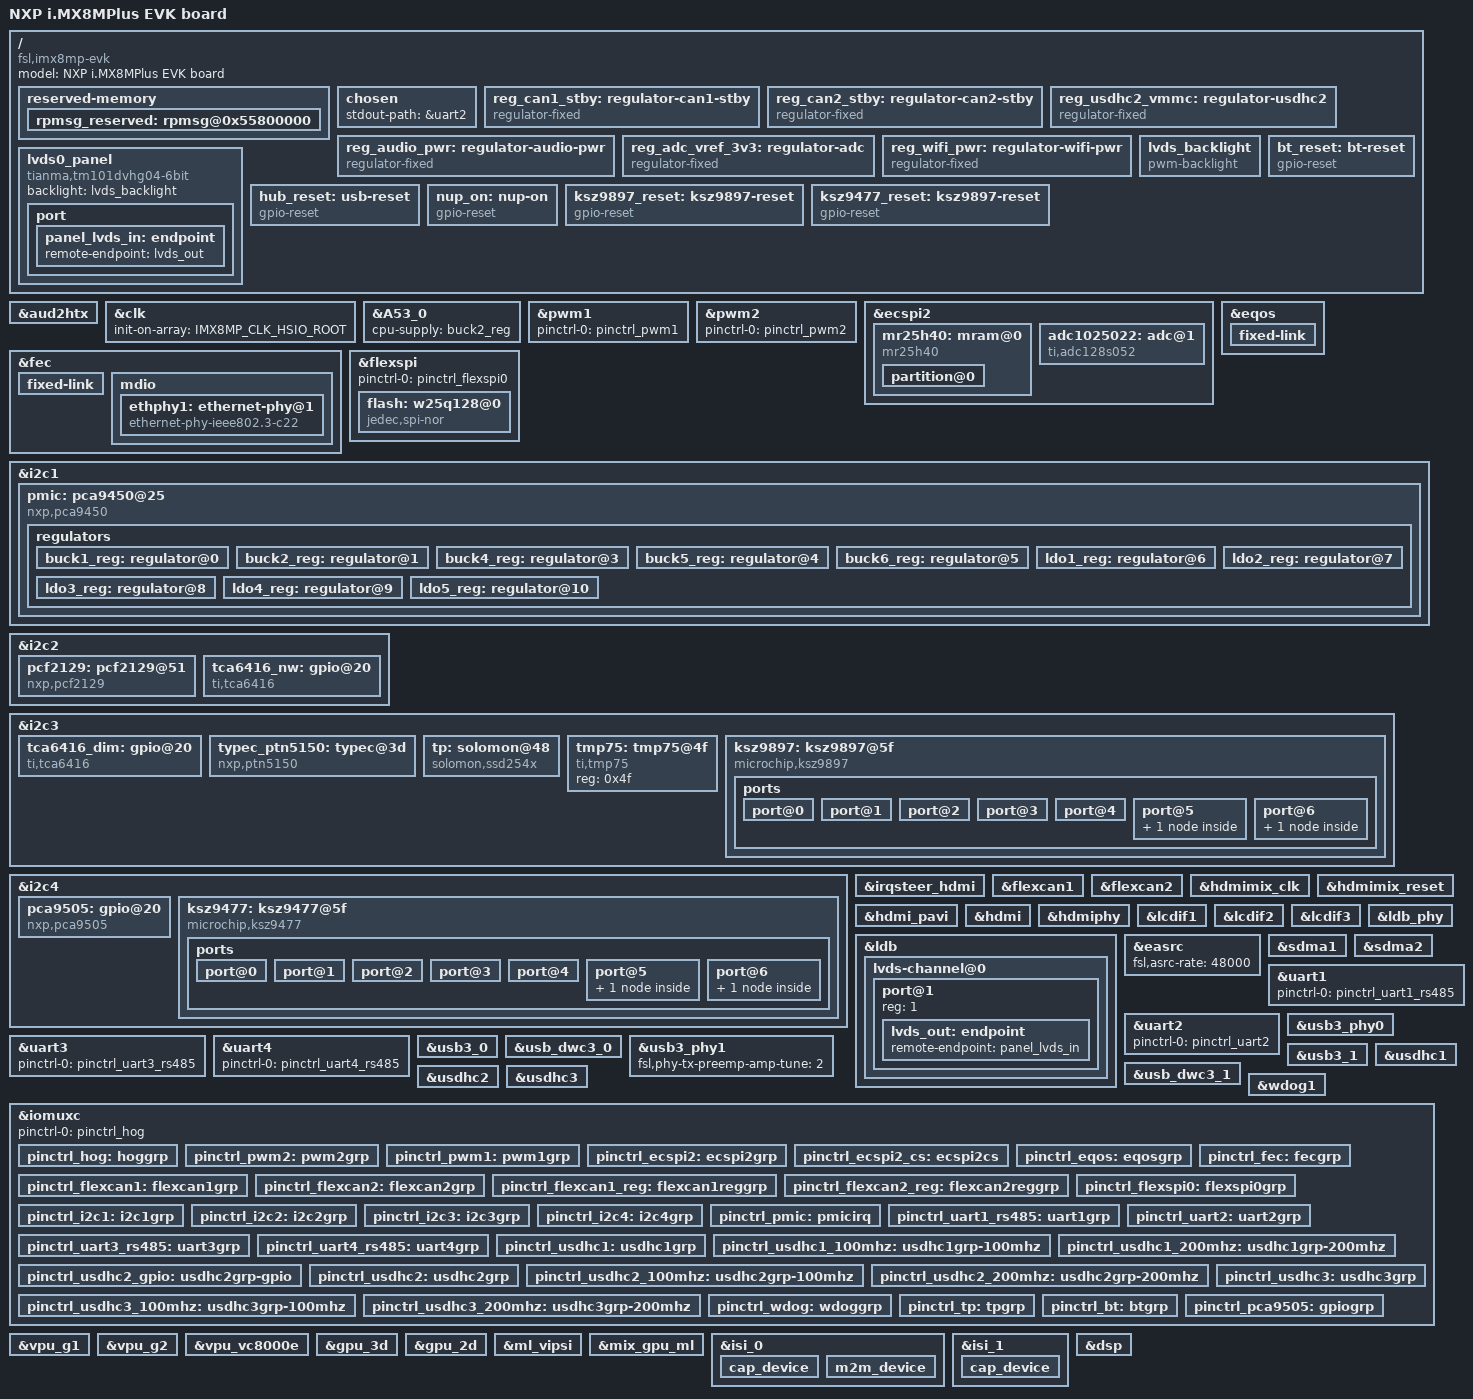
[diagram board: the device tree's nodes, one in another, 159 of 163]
// SPDX-License-Identifier: (GPL-2.0+ OR MIT)
/*
 * Copyright 2019 NXP
 */

/dts-v1/;

#include <dt-bindings/usb/pd.h>
#include "imx8mp-common.dtsi"

/ {
	model = "NXP i.MX8MPlus EVK board";
	compatible = "fsl,imx8mp-evk", "fsl,imx8mp";

	reserved-memory {
		#address-cells = <2>;
		#size-cells = <2>;
		ranges;

		rpmsg_reserved: rpmsg@0x55800000 {
			no-map;
			reg = <0 0x55800000 0 0x800000>;
		};
	};

	chosen {
		stdout-path = &uart2;
	};

	reg_can1_stby: regulator-can1-stby {
		compatible = "regulator-fixed";
		regulator-name = "can1-stby";
		pinctrl-names = "default";
		pinctrl-0 = <&pinctrl_flexcan1_reg>;
		regulator-min-microvolt = <3300000>;
		regulator-max-microvolt = <3300000>;
		gpio = <&gpio4 1 GPIO_ACTIVE_LOW>;
		enable-active-low;
	};

	reg_can2_stby: regulator-can2-stby {
		compatible = "regulator-fixed";
		regulator-name = "can2-stby";
		pinctrl-names = "default";
		pinctrl-0 = <&pinctrl_flexcan2_reg>;
		regulator-min-microvolt = <3300000>;
		regulator-max-microvolt = <3300000>;
		gpio = <&gpio1 11 GPIO_ACTIVE_LOW>;
		enable-active-low;
	        status = "okay";
	};

	reg_usdhc2_vmmc: regulator-usdhc2 {
		compatible = "regulator-fixed";
		regulator-name = "VSD_3V3";
		regulator-min-microvolt = <3300000>;
		regulator-max-microvolt = <3300000>;
		gpio = <&gpio2 19 GPIO_ACTIVE_HIGH>;
		enable-active-high;
		startup-delay-us = <100>;
		off-on-delay-us = <12000>;
	};

	reg_audio_pwr: regulator-audio-pwr {
		compatible = "regulator-fixed";
		regulator-name = "audio-pwr";
		regulator-min-microvolt = <3300000>;
		regulator-max-microvolt = <3300000>;
		gpio = <&gpio4 29 GPIO_ACTIVE_HIGH>;
		enable-active-high;
		regulator-always-on;
	};

	reg_adc_vref_3v3: regulator-adc {
                compatible = "regulator-fixed";
                regulator-name = "3V3";
                regulator-min-microvolt = <3327272>;
                regulator-max-microvolt = <3327272>;
                regulator-always-on;
        };

	reg_wifi_pwr: regulator-wifi-pwr {
                compatible = "regulator-fixed";
                regulator-name = "wifi-pwr";
                regulator-min-microvolt = <3300000>;
                regulator-max-microvolt = <3300000>;
                gpio = <&gpio2 8 GPIO_ACTIVE_HIGH>;
                enable-active-high;
                regulator-always-on;
                startup-delay-us = <10000>;
                off-on-delay-us = <12000>;
        };

	lvds_backlight: lvds_backlight {
		compatible = "pwm-backlight";
		pwms = <&pwm1 0 100000>;
		status = "okay";

		brightness-levels = < 0  1  2  3  4  5  6  7  8  9
				     10 11 12 13 14 15 16 17 18 19
				     20 21 22 23 24 25 26 27 28 29
				     30 31 32 33 34 35 36 37 38 39
				     40 41 42 43 44 45 46 47 48 49
				     50 51 52 53 54 55 56 57 58 59
				     60 61 62 63 64 65 66 67 68 69
				     70 71 72 73 74 75 76 77 78 79
				     80 81 82 83 84 85 86 87 88 89
				     90 91 92 93 94 95 96 97 98 99
				    100>;
		default-brightness-level = <80>;
	};

	lvds0_panel {
		compatible = "tianma,tm101dvhg04-6bit";
		backlight = <&lvds_backlight>;

		port {
			panel_lvds_in: endpoint {
				remote-endpoint = <&lvds_out>;
			};
		};
	};

	bt_reset: bt-reset {
		compatible = "gpio-reset";
		reset-gpios = <&gpio2 7 GPIO_ACTIVE_LOW>;
		reset-delay-us = <1000>;
		#reset-cells = <0>;
	};

	hub_reset: usb-reset {
		compatible = "gpio-reset";
		reset-gpios = <&pca9505 27 1>;
		#reset-cells = <0>;
		default-state = "off";
	};

	nup_on: nup-on {
               compatible = "gpio-reset";
               reset-gpios = <&pca9505 25 1>;
               #reset-cells = <0>;
               default-state = "off";
	};

	ksz9897_reset: ksz9897-reset {
		compatible = "gpio-reset";
		reset-gpios = <&gpio2 10 1>;
		#reset-cells = <0>;
		default-state = "off";
	};

	ksz9477_reset: ksz9897-reset {
		compatible = "gpio-reset";
		reset-gpios = <&gpio4 2 1>;
		#reset-cells = <0>;
		default-state = "off";
	};
};

&aud2htx {
	status = "okay";
};

&clk {
	init-on-array = <IMX8MP_CLK_HSIO_ROOT>;
};

&A53_0 {
	cpu-supply = <&buck2_reg>;
};

&pwm1 {
	pinctrl-names = "default";
	pinctrl-0 = <&pinctrl_pwm1>;
	status = "okay";
};

&pwm2 {
	pinctrl-names = "default";
	pinctrl-0 = <&pinctrl_pwm2>;
	status = "okay";
};

&ecspi2 {
	pinctrl-names = "default";
	fsl,spi-num-chipselects = <2>;
	num-cs = <2>;
	pinctrl-0 = <&pinctrl_ecspi2 &pinctrl_ecspi2_cs>;
	cs-gpios = <&gpio5 13 GPIO_ACTIVE_LOW
                    &gpio5 1 GPIO_ACTIVE_LOW>;
	status = "okay";

	mr25h40: mram@0 {
              #address-cells = <1>;
              #size-cells = <1>;
              compatible = "mr25h40", "jedec,spi-nor";
              reg = <0 0x00000000 0x00080000>;
              spi-max-frequency = <30000000>;

              partition@0 {
                      label = "mram";
                      reg = <0x00000000 0x00080000>;
              };
	};


        /* The actual chip is a ADC102S022, 10bit 8-channel. Driver is for a 12-bit,
        so the two MSBs will be 0 */
        adc1025022: adc@1 {
                reg = <1>;
                #address-cells = <1>;
                #size-cells = <0>;
                compatible = "ti,adc128s052";
                vref-supply = <&reg_adc_vref_3v3>;
                spi-max-frequency = <1000000>;
                status = "okay";
        };

};

&eqos {
	pinctrl-names = "default";
	pinctrl-0 = <&pinctrl_eqos>;
	phy-mode = "rgmii-id";
	resets = <&ksz9897_reset>;
	status = "okay";

        fixed-link {
                speed = <1000>;
                full-duplex;
        };
};

&fec {
	pinctrl-names = "default";
	pinctrl-0 = <&pinctrl_fec>;
	phy-mode = "rgmii-txid";
	phy-handle = <&ethphy1>;
	resets = <&ksz9477_reset>;
	fsl,magic-packet;
	status = "okay";

        fixed-link {
                speed = <1000>;
                full-duplex;
        };

	mdio {
		#address-cells = <1>;
		#size-cells = <0>;

		ethphy1: ethernet-phy@1 {
			compatible = "ethernet-phy-ieee802.3-c22";
			reg = <1>;
			micrel,led-mode = <1>;
                        eee-broken-100tx;
                        eee-broken-1000t;
		};
	};
};

&flexspi {
	pinctrl-names = "default";
	pinctrl-0 = <&pinctrl_flexspi0>;
	status = "okay";

        /*      Winbond 25Q128JWSIQ SPI NOR flash       */
        flash: w25q128@0 {
                #address-cells = <1>;
                #size-cells = <1>;
                compatible = "jedec,spi-nor";
                m25p,fast-read;
                spi-max-frequency = <40000000>;
                reg = <0>;
                status = "okay";
        };
};


&i2c1 {
	clock-frequency = <100000>;
	pinctrl-names = "default";
	pinctrl-0 = <&pinctrl_i2c1>;
	status = "okay";

	pmic: pca9450@25 {
		reg = <0x25>;
		compatible = "nxp,pca9450";
		/* PMIC PCA9450 PMIC_nINT GPIO1_IO3 */
		pinctrl-0 = <&pinctrl_pmic>;
		gpio_intr = <&gpio1 3 GPIO_ACTIVE_LOW>;

		regulators {
			#address-cells = <1>;
			#size-cells = <0>;

			pca9450,pmic-buck2-uses-i2c-dvs;
			/* Run/Standby voltage */
			pca9450,pmic-buck2-dvs-voltage = <950000>, <850000>;

			buck1_reg: regulator@0 {
				reg = <0>;
				regulator-compatible = "buck1";
				regulator-min-microvolt = <600000>;
				regulator-max-microvolt = <2187500>;
				regulator-boot-on;
				regulator-always-on;
				regulator-ramp-delay = <3125>;
			};

			buck2_reg: regulator@1 {
				reg = <1>;
				regulator-compatible = "buck2";
				regulator-min-microvolt = <600000>;
				regulator-max-microvolt = <2187500>;
				regulator-boot-on;
				regulator-always-on;
				regulator-ramp-delay = <3125>;
			};

			buck4_reg: regulator@3 {
				reg = <3>;
				regulator-compatible = "buck4";
				regulator-min-microvolt = <600000>;
				regulator-max-microvolt = <3400000>;
				regulator-boot-on;
				regulator-always-on;
			};

			buck5_reg: regulator@4 {
				reg = <4>;
				regulator-compatible = "buck5";
				regulator-min-microvolt = <600000>;
				regulator-max-microvolt = <3400000>;
				regulator-boot-on;
				regulator-always-on;
			};

			buck6_reg: regulator@5 {
				reg = <5>;
				regulator-compatible = "buck6";
				regulator-min-microvolt = <600000>;
				regulator-max-microvolt = <3400000>;
				regulator-boot-on;
				regulator-always-on;
			};

			ldo1_reg: regulator@6 {
				reg = <6>;
				regulator-compatible = "ldo1";
				regulator-min-microvolt = <1600000>;
				regulator-max-microvolt = <3300000>;
				regulator-boot-on;
				regulator-always-on;
			};

			ldo2_reg: regulator@7 {
				reg = <7>;
				regulator-compatible = "ldo2";
				regulator-min-microvolt = <800000>;
				regulator-max-microvolt = <1150000>;
				regulator-boot-on;
				regulator-always-on;
			};

			ldo3_reg: regulator@8 {
				reg = <8>;
				regulator-compatible = "ldo3";
				regulator-min-microvolt = <800000>;
				regulator-max-microvolt = <3300000>;
				regulator-boot-on;
				regulator-always-on;
			};

			ldo4_reg: regulator@9 {
				reg = <9>;
				regulator-compatible = "ldo4";
				regulator-min-microvolt = <800000>;
				regulator-max-microvolt = <3300000>;
				regulator-boot-on;
				regulator-always-on;
			};

			ldo5_reg: regulator@10 {
				reg = <10>;
				regulator-compatible = "ldo5";
				regulator-min-microvolt = <1800000>;
				regulator-max-microvolt = <3300000>;
			};
		};
	};
};

&i2c2 {
	clock-frequency = <100000>;
	pinctrl-names = "default";
	pinctrl-0 = <&pinctrl_i2c2>;
	status = "okay";

	/* RTC */
	pcf2129: pcf2129@51 {
		compatible = "nxp,pcf2129";
		reg = <0x51>;
		interrupt-parent = <&pca9505>;
		interrupts = <7 IRQ_TYPE_EDGE_FALLING>;
	};

	tca6416_nw: gpio@20 {
		compatible = "ti,tca6416";
		reg = <0x20>;
		gpio-controller;
		#gpio-cells = <2>;
	};
};

&i2c3 {
	clock-frequency = <100000>;
	pinctrl-names = "default";
	pinctrl-0 = <&pinctrl_i2c3>;
	status = "okay";

	tca6416_dim: gpio@20 {
		compatible = "ti,tca6416";
		reg = <0x20>;
		gpio-controller;
		#gpio-cells = <2>;
	};

	typec_ptn5150: typec@3d {
		compatible = "nxp,ptn5150";
		reg = <0x3d>;
		vbus-gpios = <&pca9505 18 GPIO_ACTIVE_HIGH>;
		status = "okay";
	};

	tp: solomon@48 {
		compatible = "solomon,ssd254x";
		pinctrl-names = "default";
		pinctrl-0 = <&pinctrl_tp>;
		reg = <0x48>;
		gpios = <&gpio5 3 1>, /* interrupt */
		<&tca6416_dim 0 1>; /* Reset */
	};

       /*      temperature sensor      */
       tmp75: tmp75@4f {
               compatible = "ti,tmp75";
               reg = <0x4f>;
               status = "okay";
       };

       ksz9897: ksz9897@5f {
               compatible = "microchip,ksz9897";
               reg = <0x5f>;
               phy-mode = "rgmii-txid";

               interrupt-parent = <&gpio2>;
               interrupts = <11 IRQ_TYPE_LEVEL_LOW>;
               status = "okay";
               ports {
                       #address-cells = <1>;
                       #size-cells = <0>;
                       port@0 {
                               reg = <0>;
                               label = "lan1";
                       };
                       port@1 {
                               reg = <1>;
                               label = "lan2";
                       };
                       port@2 {
                               reg = <2>;
                               label = "lan3";
                       };
                       port@3 {
                               reg = <3>;
                               label = "lan4";
                       };
                       port@4 {
                               reg = <4>;
                               label = "lan5";
                       };
                       port@5 {
                               reg = <5>;
                               label = "cpu";
                               ethernet = <&eqos>;
                               fixed-link {
                                      speed = <1000>;
                                      full-duplex;
                               };
                       };
                       port@6 {
                              reg = <6>;
                              label = "lan6";
                              fixed-link {
                                     speed = <1000>;
                                     full-duplex;
                              };
                       };
               };
       };

};

&i2c4 {
        clock-frequency = <100000>;
        pinctrl-names = "default";
        pinctrl-0 = <&pinctrl_i2c4>;
        status = "okay";

	pca9505: gpio@20 {
		compatible = "nxp,pca9505";
		reg = <0x20>;
		gpio-controller;
		#gpio-cells = <2>;
		status = "okay";
	};

	ksz9477: ksz9477@5f {
		compatible = "microchip,ksz9477";
		reg = <0x5f>;
		phy-mode = "rgmii-rxid";

		interrupt-parent = <&gpio4>;
		interrupts = <3 IRQ_TYPE_LEVEL_LOW>;
		status = "okay";
		ports {
			#address-cells = <1>;
			#size-cells = <0>;
			port@0 {
				reg = <0>;
				label = "lan1";
			};
			port@1 {
				reg = <1>;
				label = "lan2";
			};
			port@2 {
				reg = <2>;
				label = "lan3";
			};
			port@3 {
				reg = <3>;
				label = "lan4";
			};
			port@4 {
				reg = <4>;
				label = "lan5";
			};
			port@5 {
				reg = <5>;
				label = "cpu";
				ethernet = <&fec>;
				fixed-link {
					speed = <1000>;
					full-duplex;
				};
			};
			port@6 {
				reg = <6>;
				label = "lan6";
				fixed-link {
					speed = <1000>;
					full-duplex;
					};
			};
		};
	};
};


&irqsteer_hdmi {
	status = "okay";
};

&flexcan1 {
	pinctrl-names = "default";
	pinctrl-0 = <&pinctrl_flexcan1>;
	xceiver-supply = <&reg_can1_stby>;
	status = "okay";
};

&flexcan2 {
	pinctrl-names = "default";
	pinctrl-0 = <&pinctrl_flexcan2>;
	xceiver-supply = <&reg_can2_stby>;
	status = "okay";
};

&hdmimix_clk {
	status = "okay";
};

&hdmimix_reset {
	status = "okay";
};

&hdmi_pavi {
	status = "okay";
};

&hdmi {
	status = "okay";
};

&hdmiphy {
	status = "okay";
};

&lcdif1 {
	status = "okay";
};

&lcdif2 {
        status = "okay";
};

&lcdif3 {
	status = "okay";

	thres-low  = <1 2>;             /* (FIFO * 1 / 2) */
	thres-high = <3 4>;             /* (FIFO * 3 / 4) */
};

&ldb {
	status = "okay";

	lvds-channel@0 {
		fsl,data-mapping = "jeida";
		fsl,data-width = <24>;
		status = "okay";

		port@1 {
			reg = <1>;

			lvds_out: endpoint {
				remote-endpoint = <&panel_lvds_in>;
			};
		};
	};
};

&ldb_phy {
	status = "okay";
};

&easrc {
	fsl,asrc-rate  = <48000>;
	status = "okay";
};

&sdma1 {
	status = "okay";
};

&sdma2 {
	status = "okay";
};

&uart1 { /* For RS485 */
	pinctrl-names = "default";
	pinctrl-0 = <&pinctrl_uart1_rs485>;
	//assigned-clocks = <&clk IMX8MP_CLK_UART1>;
	//assigned-clock-parents = <&clk IMX8MP_SYS_PLL1_80M>;
	status = "okay";
};

&uart2 {
	/* console */
	pinctrl-names = "default";
	pinctrl-0 = <&pinctrl_uart2>;
	status = "okay";
};

&uart3 { /* For RS485 */
	pinctrl-names = "default";
	pinctrl-0 = <&pinctrl_uart3_rs485>;
	//assigned-clocks = <&clk IMX8MP_CLK_UART3>;
	//assigned-clock-parents = <&clk IMX8MP_SYS_PLL1_80M>;
	//fsl,uart-has-rtscts;
	status = "okay";
	//status = "disable";
};

&uart4 { /* for RS485-A,B */
	pinctrl-names = "default";
	pinctrl-0 = <&pinctrl_uart4_rs485>;
	//assigned-clocks = <&clk IMX8MP_CLK_UART3>;
	//assigned-clock-parents = <&clk IMX8MP_SYS_PLL1_80M>;
	//fsl,uart-has-rtscts;
	status = "okay";
	//status = "disable";
};

&usb3_phy0 {
	//vbus-power-supply = <&typec1_ptn5150>;
	fsl,phy-tx-vref-tune = <6>;
	fsl,phy-tx-rise-tune = <0>;
	fsl,phy-tx-preemp-amp-tune = <3>;
	fsl,phy-comp-dis-tune = <7>;
	fsl,pcs-tx-deemph-3p5db = <0x21>;
	fsl,phy-pcs-tx-swing-full = <0x7f>;
	status = "okay";
};

&usb3_0 {
	status = "okay";
};

&usb_dwc3_0 {
	//dr_mode = "peripheral";
	//dr_mode = "host";
	dr_mode = "otg";
	extcon = <&typec_ptn5150>;
	hnp-disable;
	srp-disable;
	adp-disable;
	maximum-speed = "full-speed";
	//usb-role-switch;
	status = "okay";
};

&usb3_phy1 {
	fsl,phy-tx-preemp-amp-tune = <2>;
	status = "okay";
};

&usb3_1 {
	status = "okay";
};

&usb_dwc3_1 {
	//dr_mode = "peripheral";
	resets = <&hub_reset>;
        dr_mode = "host";
        status = "okay";
};

&usdhc1 { /* wifi */
	pinctrl-names = "default", "state_100mhz", "state_200mhz";
	pinctrl-0 = <&pinctrl_usdhc1>;
	pinctrl-1 = <&pinctrl_usdhc1_100mhz>;
	pinctrl-2 = <&pinctrl_usdhc1_200mhz>;
	bus-width = <4>;
        vmmc-supply = <&reg_wifi_pwr>;
	non-removable;
	keep-power-in-suspend;
	enable-sdio-wakeup;
	status = "okay";
};

&usdhc2 {
	pinctrl-names = "default", "state_100mhz", "state_200mhz";
	pinctrl-0 = <&pinctrl_usdhc2>, <&pinctrl_usdhc2_gpio>;
	pinctrl-1 = <&pinctrl_usdhc2_100mhz>, <&pinctrl_usdhc2_gpio>;
	pinctrl-2 = <&pinctrl_usdhc2_200mhz>, <&pinctrl_usdhc2_gpio>;
	cd-gpios = <&gpio2 12 GPIO_ACTIVE_LOW>;
	vmmc-supply = <&reg_usdhc2_vmmc>;
	bus-width = <4>;
	status = "okay";
};

&usdhc3 {
	pinctrl-names = "default", "state_100mhz", "state_200mhz";
	pinctrl-0 = <&pinctrl_usdhc3>;
	pinctrl-1 = <&pinctrl_usdhc3_100mhz>;
	pinctrl-2 = <&pinctrl_usdhc3_200mhz>;
	bus-width = <8>;
	non-removable;
	status = "okay";
};

&wdog1 {
	pinctrl-names = "default";
	pinctrl-0 = <&pinctrl_wdog>;
	fsl,ext-reset-output;
	status = "okay";
};

&iomuxc {
	pinctrl-names = "default";
	pinctrl-0 = <&pinctrl_hog>;

	pinctrl_hog: hoggrp {
		fsl,pins = <
			MX8MP_IOMUXC_SAI2_MCLK__GPIO4_IO27		0x19 /* HW_FIRE_IN */
			MX8MP_IOMUXC_SAI2_TXFS__GPIO4_IO24		0x19 /* SYS_FAULT_IN */
			MX8MP_IOMUXC_SAI2_TXC__GPIO4_IO25		0x19 /* HW_FIRE_OUT  */
			MX8MP_IOMUXC_SAI2_TXD0__GPIO4_IO26		0x19 /* BUF_nALRM_BUS */
			MX8MP_IOMUXC_SAI2_RXD0__GPIO4_IO23		0x19 /* xCLP_SYNC_UNBUF */
			MX8MP_IOMUXC_SAI2_RXFS__GPIO4_IO21		0x19 /* BUF_SYS_SYNC_IN */
			MX8MP_IOMUXC_SAI3_MCLK__GPIO5_IO02		0x19 /* INT_ADIN1200 */
			MX8MP_IOMUXC_SAI3_TXFS__GPIO4_IO31		0x19 /* INT_ADIN1100 */
			MX8MP_IOMUXC_SAI3_TXC__GPIO5_IO00		0x19 /* INT_N_SFP2_10BASE2 */
			MX8MP_IOMUXC_SAI3_RXFS__GPIO4_IO28		0x19 /* INT_N_SFP1_10BASE1 */
			MX8MP_IOMUXC_SPDIF_RX__GPIO5_IO04		0x19 /* EXPANDER_nINT */
			MX8MP_IOMUXC_SPDIF_EXT_CLK__GPIO5_IO05		0x19 /* USB_INT */
			MX8MP_IOMUXC_SD2_WP__GPIO2_IO20			0x19 /* nINT_NFC */
			MX8MP_IOMUXC_SD2_RESET_B__GPIO2_IO19		0x19 /* SYS_SYNC_OUT */
			MX8MP_IOMUXC_SAI1_TXD6__GPIO4_IO18		0x19 /* ONC_PM_RESET */
			MX8MP_IOMUXC_SAI1_RXFS__GPIO4_IO00		0x19 /* PME_N */
			MX8MP_IOMUXC_SAI5_RXFS__GPIO3_IO19		0x19 
			MX8MP_IOMUXC_GPIO1_IO05__GPIO1_IO05		0x19 /* BOARD_ID_01 */
			MX8MP_IOMUXC_GPIO1_IO06__GPIO1_IO06		0x19 /* BOARD_ID_02 */
			MX8MP_IOMUXC_GPIO1_IO07__GPIO1_IO07		0x19 /* BOARD_ID_03 */
			MX8MP_IOMUXC_GPIO1_IO13__GPIO1_IO13		0x19 /* BOARD_REV_01 */
			MX8MP_IOMUXC_GPIO1_IO14__GPIO1_IO14		0x19 /* BOARD_REV_02 */
			MX8MP_IOMUXC_GPIO1_IO01__GPIO1_IO01		0x19 /* OPT_NW_ID */
			MX8MP_IOMUXC_GPIO1_IO15__GPIO1_IO15		0x19 
			MX8MP_IOMUXC_GPIO1_IO10__GPIO1_IO10		0x19 
			MX8MP_IOMUXC_SAI1_TXD7__GPIO4_IO19		0x19 /* GPIO_RESET */
		>;
	};

	pinctrl_pwm2: pwm2grp {
		fsl,pins = <
			MX8MP_IOMUXC_GPIO1_IO09__PWM2_OUT	0x116
		>;
	};

	pinctrl_pwm1: pwm1grp {
		fsl,pins = <
			MX8MP_IOMUXC_GPIO1_IO08__PWM1_OUT	0x116
		>;
	};

	pinctrl_pwm2: pwm2grp {
		fsl,pins = <
			MX8MP_IOMUXC_GPIO1_IO09__PWM2_OUT	0x116
		>;
	};

	pinctrl_ecspi2: ecspi2grp {
		fsl,pins = <
			MX8MP_IOMUXC_ECSPI2_SCLK__ECSPI2_SCLK		0x82
			MX8MP_IOMUXC_ECSPI2_MOSI__ECSPI2_MOSI		0x82
			MX8MP_IOMUXC_ECSPI2_MISO__ECSPI2_MISO		0x82
			MX8MP_IOMUXC_SAI3_RXC__GPIO4_IO29               0x19 /* GPIO_ECSPI2_nWP */
                        MX8MP_IOMUXC_SAI3_RXD__GPIO4_IO30               0x19 /* GPIO_ECSPI2_nHLD */
		>;
	};

	pinctrl_ecspi2_cs: ecspi2cs {
		fsl,pins = <
			MX8MP_IOMUXC_ECSPI2_SS0__GPIO5_IO13             0x40000 /* cs0 */
                        MX8MP_IOMUXC_SAI3_TXD__GPIO5_IO01               0x40000 /* cs1 */
		>;
	};

	pinctrl_eqos: eqosgrp {
		fsl,pins = <
			MX8MP_IOMUXC_ENET_MDC__ENET_QOS_MDC	0x3
			MX8MP_IOMUXC_ENET_MDIO__ENET_QOS_MDIO	0x3
			MX8MP_IOMUXC_ENET_RD0__ENET_QOS_RGMII_RD0	0x91
			MX8MP_IOMUXC_ENET_RD1__ENET_QOS_RGMII_RD1	0x91
			MX8MP_IOMUXC_ENET_RD2__ENET_QOS_RGMII_RD2	0x91
			MX8MP_IOMUXC_ENET_RD3__ENET_QOS_RGMII_RD3	0x91
			MX8MP_IOMUXC_ENET_RXC__CCM_ENET_QOS_CLOCK_GENERATE_RX_CLK	0x91
			MX8MP_IOMUXC_ENET_RX_CTL__ENET_QOS_RGMII_RX_CTL	0x91
			MX8MP_IOMUXC_ENET_TD0__ENET_QOS_RGMII_TD0		0x1f
			MX8MP_IOMUXC_ENET_TD1__ENET_QOS_RGMII_TD1		0x1f
			MX8MP_IOMUXC_ENET_TD2__ENET_QOS_RGMII_TD2		0x1f
			MX8MP_IOMUXC_ENET_TD3__ENET_QOS_RGMII_TD3		0x1f
			MX8MP_IOMUXC_ENET_TX_CTL__ENET_QOS_RGMII_TX_CTL	0x1f
			MX8MP_IOMUXC_ENET_TXC__CCM_ENET_QOS_CLOCK_GENERATE_TX_CLK	0x1f
			MX8MP_IOMUXC_SD1_RESET_B__GPIO2_IO10		0x19
			MX8MP_IOMUXC_SD1_STROBE__GPIO2_IO11		0x19 /* ksz9897 switch INT */
			MX8MP_IOMUXC_SAI5_RXD0__GPIO3_IO21		0x19 /* ENET_PME_N */
		>;
	};

	pinctrl_fec: fecgrp {
		fsl,pins = <
			MX8MP_IOMUXC_SAI1_RXD2__ENET1_MDC		0x3
			MX8MP_IOMUXC_SAI1_RXD3__ENET1_MDIO		0x3
			MX8MP_IOMUXC_SAI1_RXD4__ENET1_RGMII_RD0		0x91
			MX8MP_IOMUXC_SAI1_RXD5__ENET1_RGMII_RD1		0x91
			MX8MP_IOMUXC_SAI1_RXD6__ENET1_RGMII_RD2		0x91
			MX8MP_IOMUXC_SAI1_RXD7__ENET1_RGMII_RD3		0x91
			MX8MP_IOMUXC_SAI1_TXC__ENET1_RGMII_RXC		0x91
			MX8MP_IOMUXC_SAI1_TXFS__ENET1_RGMII_RX_CTL	0x91
			MX8MP_IOMUXC_SAI1_TXD0__ENET1_RGMII_TD0		0x1f
			MX8MP_IOMUXC_SAI1_TXD1__ENET1_RGMII_TD1		0x1f
			MX8MP_IOMUXC_SAI1_TXD2__ENET1_RGMII_TD2		0x1f
			MX8MP_IOMUXC_SAI1_TXD3__ENET1_RGMII_TD3		0x1f
			MX8MP_IOMUXC_SAI1_TXD4__ENET1_RGMII_TX_CTL	0x1f
			MX8MP_IOMUXC_SAI1_TXD5__ENET1_RGMII_TXC		0x1f
			MX8MP_IOMUXC_SAI1_RXD0__GPIO4_IO02		0x19
			MX8MP_IOMUXC_SAI1_RXD1__GPIO4_IO03		0x19 /* ksz9477 switch INT */
		>;
	};

	pinctrl_flexcan1: flexcan1grp {
		fsl,pins = <
			MX8MP_IOMUXC_SAI5_RXD2__CAN1_RX          0x154
			MX8MP_IOMUXC_SAI5_RXD1__CAN1_TX          0x154
		>;
	};

	pinctrl_flexcan2: flexcan2grp {
		fsl,pins = <
			MX8MP_IOMUXC_SAI5_MCLK__CAN2_RX		0x154
			MX8MP_IOMUXC_SAI5_RXD3__CAN2_TX		0x154
		>;
	};

	pinctrl_flexcan1_reg: flexcan1reggrp {
		fsl,pins = <
			MX8MP_IOMUXC_SAI1_RXC__GPIO4_IO01	0x154	/* CAN1_STBY */
		>;
	};

	pinctrl_flexcan2_reg: flexcan2reggrp {
		fsl,pins = <
			MX8MP_IOMUXC_GPIO1_IO11__GPIO1_IO11	0x154	/* CAN2_STBY */
		>;
	};

	pinctrl_flexspi0: flexspi0grp {
		fsl,pins = <
			MX8MP_IOMUXC_NAND_ALE__FLEXSPI_A_SCLK		0x1c2
			MX8MP_IOMUXC_NAND_CE0_B__FLEXSPI_A_SS0_B	0x82
			MX8MP_IOMUXC_NAND_DATA00__FLEXSPI_A_DATA00	0x82
			MX8MP_IOMUXC_NAND_DATA01__FLEXSPI_A_DATA01	0x82
			MX8MP_IOMUXC_NAND_DATA02__FLEXSPI_A_DATA02	0x82
			MX8MP_IOMUXC_NAND_DATA03__FLEXSPI_A_DATA03	0x82
		>;
	};

	pinctrl_i2c1: i2c1grp {
		fsl,pins = <
			MX8MP_IOMUXC_I2C1_SCL__I2C1_SCL		0x400001c3
			MX8MP_IOMUXC_I2C1_SDA__I2C1_SDA		0x400001c3
		>;
	};

	pinctrl_i2c2: i2c2grp {
		fsl,pins = <
			MX8MP_IOMUXC_I2C2_SCL__I2C2_SCL			0x400001c3
			MX8MP_IOMUXC_I2C2_SDA__I2C2_SDA			0x400001c3
		>;
	};

	pinctrl_i2c3: i2c3grp {
		fsl,pins = <
			MX8MP_IOMUXC_I2C3_SCL__I2C3_SCL			0x400001c3
			MX8MP_IOMUXC_I2C3_SDA__I2C3_SDA			0x400001c3
		>;
	};

	pinctrl_i2c4: i2c4grp {
		fsl,pins = <
			MX8MP_IOMUXC_I2C4_SCL__I2C4_SCL			0x400001c3
			MX8MP_IOMUXC_I2C4_SDA__I2C4_SDA			0x400001c3
		>;
	};


	pinctrl_pmic: pmicirq {
		fsl,pins = <
			MX8MP_IOMUXC_GPIO1_IO03__GPIO1_IO03	0x41
		>;
	};


	pinctrl_uart1_rs485: uart1grp {
		fsl,pins = <
			MX8MP_IOMUXC_UART1_RXD__UART1_DCE_RX	0x140
			MX8MP_IOMUXC_UART1_TXD__UART1_DCE_TX	0x140
			MX8MP_IOMUXC_UART3_RXD__GPIO5_IO26	0x140
			MX8MP_IOMUXC_UART3_TXD__GPIO5_IO27	0x140
		>;
	};

	pinctrl_uart2: uart2grp {
		fsl,pins = <
			MX8MP_IOMUXC_UART2_RXD__UART2_DCE_RX	0x49
			MX8MP_IOMUXC_UART2_TXD__UART2_DCE_TX	0x49
		>;
	};

	pinctrl_uart3_rs485: uart3grp {
		fsl,pins = <
			MX8MP_IOMUXC_ECSPI1_SCLK__UART3_DCE_RX		0x140
			MX8MP_IOMUXC_ECSPI1_MOSI__UART3_DCE_TX		0x140
			MX8MP_IOMUXC_ECSPI1_SS0__GPIO5_IO09		0x140
			MX8MP_IOMUXC_ECSPI1_MISO__GPIO5_IO08		0x140
		>;
	};

	pinctrl_uart4_rs485: uart4grp {
		fsl,pins = <
			MX8MP_IOMUXC_UART4_RXD__UART4_DCE_RX    	0x140
			MX8MP_IOMUXC_UART4_TXD__UART4_DCE_TX    	0x140
                        MX8MP_IOMUXC_HDMI_DDC_SCL__GPIO3_IO26           0x140 /* RS485-A AIO_TXENA  */
                        MX8MP_IOMUXC_HDMI_DDC_SDA__GPIO3_IO27           0x140 /* RS485-A AIO_nRXENA */
			MX8MP_IOMUXC_HDMI_CEC__GPIO3_IO28               0x140 /* RS485-B AIO_nRXENB */
			MX8MP_IOMUXC_HDMI_HPD__GPIO3_IO29               0x140 /* RS485-B AIO_TXENB */
		>;
	};

	pinctrl_usdhc1: usdhc1grp {
		fsl,pins = <
			MX8MP_IOMUXC_SD1_CLK__USDHC1_CLK	0x190
			MX8MP_IOMUXC_SD1_CMD__USDHC1_CMD	0x1d0
			MX8MP_IOMUXC_SD1_DATA0__USDHC1_DATA0	0x1d0
			MX8MP_IOMUXC_SD1_DATA1__USDHC1_DATA1	0x1d0
			MX8MP_IOMUXC_SD1_DATA2__USDHC1_DATA2	0x1d0
			MX8MP_IOMUXC_SD1_DATA3__USDHC1_DATA3	0x1d0
			MX8MP_IOMUXC_SD1_DATA6__GPIO2_IO08      0x19 /* WL_REG_ON */
			MX8MP_IOMUXC_SD1_DATA7__GPIO2_IO09      0x19 /* WL_HOST_WAKE */
		>;
	};

	pinctrl_usdhc1_100mhz: usdhc1grp-100mhz {
		fsl,pins = <
			MX8MP_IOMUXC_SD1_CLK__USDHC1_CLK	0x194
			MX8MP_IOMUXC_SD1_CMD__USDHC1_CMD	0x1d4
			MX8MP_IOMUXC_SD1_DATA0__USDHC1_DATA0	0x1d4
			MX8MP_IOMUXC_SD1_DATA1__USDHC1_DATA1	0x1d4
			MX8MP_IOMUXC_SD1_DATA2__USDHC1_DATA2	0x1d4
			MX8MP_IOMUXC_SD1_DATA3__USDHC1_DATA3	0x1d4
			MX8MP_IOMUXC_SD1_DATA6__GPIO2_IO08      0x19 /* WL_REG_ON */
			MX8MP_IOMUXC_SD1_DATA7__GPIO2_IO09      0x19 /* WL_HOST_WAKE */
		>;
	};

	pinctrl_usdhc1_200mhz: usdhc1grp-200mhz {
		fsl,pins = <
			MX8MP_IOMUXC_SD1_CLK__USDHC1_CLK	0x196
			MX8MP_IOMUXC_SD1_CMD__USDHC1_CMD	0x1d6
			MX8MP_IOMUXC_SD1_DATA0__USDHC1_DATA0	0x1d6
			MX8MP_IOMUXC_SD1_DATA1__USDHC1_DATA1	0x1d6
			MX8MP_IOMUXC_SD1_DATA2__USDHC1_DATA2	0x1d6
			MX8MP_IOMUXC_SD1_DATA3__USDHC1_DATA3	0x1d6
			MX8MP_IOMUXC_SD1_DATA6__GPIO2_IO08      0x19 /* WL_REG_ON */
			MX8MP_IOMUXC_SD1_DATA7__GPIO2_IO09      0x19 /* WL_HOST_WAKE */
		>;
	};

	pinctrl_usdhc2_gpio: usdhc2grp-gpio {
		fsl,pins = <
			MX8MP_IOMUXC_SD2_CD_B__GPIO2_IO12 	0x1c4
		>;
	};

	pinctrl_usdhc2: usdhc2grp {
		fsl,pins = <
			MX8MP_IOMUXC_SD2_CLK__USDHC2_CLK	0x190
			MX8MP_IOMUXC_SD2_CMD__USDHC2_CMD	0x1d0
			MX8MP_IOMUXC_SD2_DATA0__USDHC2_DATA0	0x1d0
			MX8MP_IOMUXC_SD2_DATA1__USDHC2_DATA1	0x1d0
			MX8MP_IOMUXC_SD2_DATA2__USDHC2_DATA2	0x1d0
			MX8MP_IOMUXC_SD2_DATA3__USDHC2_DATA3	0x1d0
			MX8MP_IOMUXC_GPIO1_IO04__USDHC2_VSELECT	0xc1
		>;
	};

	pinctrl_usdhc2_100mhz: usdhc2grp-100mhz {
		fsl,pins = <
			MX8MP_IOMUXC_SD2_CLK__USDHC2_CLK	0x194
			MX8MP_IOMUXC_SD2_CMD__USDHC2_CMD	0x1d4
			MX8MP_IOMUXC_SD2_DATA0__USDHC2_DATA0	0x1d4
			MX8MP_IOMUXC_SD2_DATA1__USDHC2_DATA1	0x1d4
			MX8MP_IOMUXC_SD2_DATA2__USDHC2_DATA2	0x1d4
			MX8MP_IOMUXC_SD2_DATA3__USDHC2_DATA3	0x1d4
			MX8MP_IOMUXC_GPIO1_IO04__USDHC2_VSELECT 0xc1
		>;
	};

	pinctrl_usdhc2_200mhz: usdhc2grp-200mhz {
		fsl,pins = <
			MX8MP_IOMUXC_SD2_CLK__USDHC2_CLK	0x196
			MX8MP_IOMUXC_SD2_CMD__USDHC2_CMD	0x1d6
			MX8MP_IOMUXC_SD2_DATA0__USDHC2_DATA0	0x1d6
			MX8MP_IOMUXC_SD2_DATA1__USDHC2_DATA1	0x1d6
			MX8MP_IOMUXC_SD2_DATA2__USDHC2_DATA2	0x1d6
			MX8MP_IOMUXC_SD2_DATA3__USDHC2_DATA3	0x1d6
			MX8MP_IOMUXC_GPIO1_IO04__USDHC2_VSELECT 0xc1
		>;
	};

	pinctrl_usdhc3: usdhc3grp {
		fsl,pins = <
			MX8MP_IOMUXC_NAND_WE_B__USDHC3_CLK	0x190
			MX8MP_IOMUXC_NAND_WP_B__USDHC3_CMD	0x1d0
			MX8MP_IOMUXC_NAND_DATA04__USDHC3_DATA0	0x1d0
			MX8MP_IOMUXC_NAND_DATA05__USDHC3_DATA1	0x1d0
			MX8MP_IOMUXC_NAND_DATA06__USDHC3_DATA2	0x1d0
			MX8MP_IOMUXC_NAND_DATA07__USDHC3_DATA3	0x1d0
			MX8MP_IOMUXC_NAND_RE_B__USDHC3_DATA4	0x1d0
			MX8MP_IOMUXC_NAND_CE2_B__USDHC3_DATA5	0x1d0
			MX8MP_IOMUXC_NAND_CE3_B__USDHC3_DATA6	0x1d0
			MX8MP_IOMUXC_NAND_CLE__USDHC3_DATA7	0x1d0
			MX8MP_IOMUXC_NAND_CE1_B__USDHC3_STROBE	0x190
		>;
	};

	pinctrl_usdhc3_100mhz: usdhc3grp-100mhz {
		fsl,pins = <
			MX8MP_IOMUXC_NAND_WE_B__USDHC3_CLK	0x194
			MX8MP_IOMUXC_NAND_WP_B__USDHC3_CMD	0x1d4
			MX8MP_IOMUXC_NAND_DATA04__USDHC3_DATA0	0x1d4
			MX8MP_IOMUXC_NAND_DATA05__USDHC3_DATA1	0x1d4
			MX8MP_IOMUXC_NAND_DATA06__USDHC3_DATA2	0x1d4
			MX8MP_IOMUXC_NAND_DATA07__USDHC3_DATA3	0x1d4
			MX8MP_IOMUXC_NAND_RE_B__USDHC3_DATA4	0x1d4
			MX8MP_IOMUXC_NAND_CE2_B__USDHC3_DATA5	0x1d4
			MX8MP_IOMUXC_NAND_CE3_B__USDHC3_DATA6	0x1d4
			MX8MP_IOMUXC_NAND_CLE__USDHC3_DATA7	0x1d4
			MX8MP_IOMUXC_NAND_CE1_B__USDHC3_STROBE	0x194
		>;
	};

	pinctrl_usdhc3_200mhz: usdhc3grp-200mhz {
		fsl,pins = <
			MX8MP_IOMUXC_NAND_WE_B__USDHC3_CLK	0x196
			MX8MP_IOMUXC_NAND_WP_B__USDHC3_CMD	0x1d6
			MX8MP_IOMUXC_NAND_DATA04__USDHC3_DATA0	0x1d6
			MX8MP_IOMUXC_NAND_DATA05__USDHC3_DATA1	0x1d6
			MX8MP_IOMUXC_NAND_DATA06__USDHC3_DATA2	0x1d6
			MX8MP_IOMUXC_NAND_DATA07__USDHC3_DATA3	0x1d6
			MX8MP_IOMUXC_NAND_RE_B__USDHC3_DATA4	0x1d6
			MX8MP_IOMUXC_NAND_CE2_B__USDHC3_DATA5	0x1d6
			MX8MP_IOMUXC_NAND_CE3_B__USDHC3_DATA6	0x1d6
			MX8MP_IOMUXC_NAND_CLE__USDHC3_DATA7	0x1d6
			MX8MP_IOMUXC_NAND_CE1_B__USDHC3_STROBE	0x196
		>;
	};

	pinctrl_wdog: wdoggrp {
		fsl,pins = <
			MX8MP_IOMUXC_GPIO1_IO02__WDOG1_WDOG_B	0xc6
		>;
	};


	pinctrl_tp: tpgrp {
		fsl,pins = <
			MX8MP_IOMUXC_SPDIF_TX__GPIO5_IO03      0x1c4
		>;
	};

	pinctrl_bt: btgrp {
		fsl,pins = <
			MX8MP_IOMUXC_SD1_DATA5__GPIO2_IO07        0x19 /* BT_REG_ON */
			MX8MP_IOMUXC_SD1_DATA4__GPIO2_IO06        0x19 /* BT_DEV_WAKE */
		>;
	};

	pinctrl_pca9505: gpiogrp {
		fsl,pins = <
			MX8MP_IOMUXC_SAI2_RXC__GPIO4_IO22		0x19 /* IO_INT */
		>;
	};
};

&vpu_g1 {
	status = "okay";
};

&vpu_g2 {
	status = "okay";
};

&vpu_vc8000e {
	status = "okay";
};

&gpu_3d {
	status = "okay";
};

&gpu_2d {
	status = "okay";
};

&ml_vipsi {
	status = "okay";
};

&mix_gpu_ml {
	status = "okay";
};


&isi_0 {
	status = "okay";

	cap_device {
		status = "okay";
	};

	m2m_device {
		status = "okay";
	};
};

&isi_1 {
	status = "okay";

	cap_device {
		status = "okay";
	};
};

&dsp {
	status = "okay";
};
